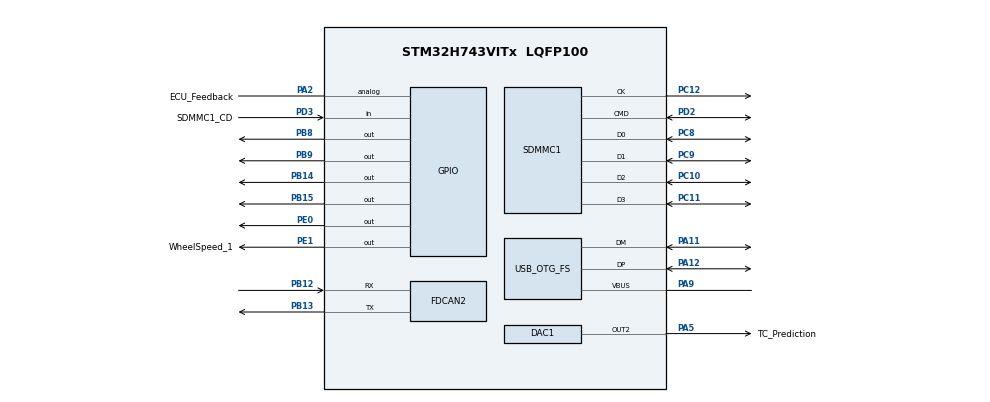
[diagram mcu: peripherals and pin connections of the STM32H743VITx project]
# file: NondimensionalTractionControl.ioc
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CORTEX_M7.AccessPermission_S-Cortex_Memory_Protection_Unit_Region1_Settings_S=MPU_REGION_PRIV_RO
CORTEX_M7.BaseAddress_S-Cortex_Memory_Protection_Unit_Region1_Settings_S=0x08000000
CORTEX_M7.CPU_DCache=Enabled
CORTEX_M7.CPU_ICache=Enabled
CORTEX_M7.Enable_S-Cortex_Memory_Protection_Unit_Region1_Settings_S=MPU_REGION_ENABLE
CORTEX_M7.IsCacheable_S-Cortex_Memory_Protection_Unit_Region1_Settings_S=MPU_ACCESS_CACHEABLE
CORTEX_M7.Size_S-Cortex_Memory_Protection_Unit_Region1_Settings_S=MPU_REGION_SIZE_2MB
CORTEX_M7.TypeExtField_S-Cortex_Memory_Protection_Unit_Region1_Settings_S=MPU_TEX_LEVEL1
CORTEX_M7.default_mode_Activation=1
DAC1.DAC_Channel-DAC_OUT2=DAC_CHANNEL_2
Dma.DMA_GENERATOR0.0.Direction=DMA_PERIPH_TO_MEMORY
Dma.DMA_GENERATOR0.0.EventEnable=DISABLE
Dma.DMA_GENERATOR0.0.FIFOMode=DMA_FIFOMODE_DISABLE
Dma.DMA_GENERATOR0.0.Instance=DMA1_Stream0
Dma.DMA_GENERATOR0.0.MemDataAlignment=DMA_MDATAALIGN_WORD
Dma.DMA_GENERATOR0.0.MemInc=DMA_MINC_ENABLE
Dma.DMA_GENERATOR0.0.Mode=DMA_CIRCULAR
Dma.DMA_GENERATOR0.0.PeriphDataAlignment=DMA_PDATAALIGN_WORD
Dma.DMA_GENERATOR0.0.PeriphInc=DMA_PINC_DISABLE
Dma.DMA_GENERATOR0.0.Polarity=HAL_DMAMUX_REQ_GEN_RISING
Dma.DMA_GENERATOR0.0.Priority=DMA_PRIORITY_HIGH
Dma.DMA_GENERATOR0.0.RequestNumber=1
Dma.DMA_GENERATOR0.0.SignalID=NONE
Dma.DMA_GENERATOR0.0.SyncEnable=DISABLE
Dma.DMA_GENERATOR0.0.SyncPolarity=HAL_DMAMUX_SYNC_NO_EVENT
Dma.DMA_GENERATOR0.0.SyncRequestNumber=1
Dma.DMA_GENERATOR0.0.SyncSignalID=NONE
Dma.Request0=DMA_GENERATOR0
FDCAN2.CalculateBaudRateNominal=166666
FDCAN2.CalculateTimeBitNominal=6000
FDCAN2.CalculateTimeQuantumNominal=2000.0
FREERTOS.Tasks01=defaultTask,24,128,StartDefaultTask,Default,NULL,Dynamic,NULL,NULL
FREERTOS.configUSE_NEWLIB_REENTRANT=1
IWDG1.Prescaler=IWDG_PRESCALER_32
IWDG1.Reload=999
IWDG1.Window=500
Mcu.Family=STM32H7
Mcu.Name=STM32H743VITx
Mcu.Package=LQFP100
NVIC.DMA1_Stream0_IRQn=true\:10\:0\:true\:false\:true\:true\:true\:true\:true
NVIC.DMAMUX1_OVR_IRQn=true\:5\:0\:false\:false\:true\:false\:false\:true\:true
NVIC.OTG_FS_IRQn=true\:5\:0\:false\:false\:true\:true\:false\:true\:true
NVIC.PriorityGroup=NVIC_PRIORITYGROUP_4
NVIC.TIM2_IRQn=true\:5\:0\:false\:false\:true\:true\:true\:true\:true
NVIC.TIM6_DAC_IRQn=true\:5\:0\:false\:false\:true\:false\:false\:true\:true
NVIC.TimeBase=TIM6_DAC_IRQn
NVIC.TimeBaseIP=TIM6
PA11.Mode=Device_Only
PA11.Signal=USB_OTG_FS_DM
PA12.Mode=Device_Only
PA12.Signal=USB_OTG_FS_DP
PA13\ (JTMS/SWDIO).Mode=Trace_Asynchronous_SW
PA13\ (JTMS/SWDIO).Signal=DEBUG_JTMS-SWDIO
PA14\ (JTCK/SWCLK).Mode=Trace_Asynchronous_SW
PA14\ (JTCK/SWCLK).Signal=DEBUG_JTCK-SWCLK
PA2.GPIO_Label=ECU_Feedback
PA2.Signal=GPIO_Analog
PA5.GPIO_Label=TC_Prediction
PA5.Signal=COMP_DAC12_group
PA9.Mode=Activate_VBUS
PA9.Signal=USB_OTG_FS_VBUS
PB12.Mode=FDCAN_Activate
PB12.Signal=FDCAN2_RX
PB13.Mode=FDCAN_Activate
PB13.Signal=FDCAN2_TX
PB14.Signal=GPIO_Output
PB15.Signal=GPIO_Output
PB3\ (JTDO/TRACESWO).Mode=Trace_Asynchronous_SW
PB3\ (JTDO/TRACESWO).Signal=DEBUG_JTDO-SWO
PB8.Signal=GPIO_Output
PB9.Signal=GPIO_Output
PC10.Mode=SD_4_bits_Wide_bus
PC10.Signal=SDMMC1_D2
PC11.Mode=SD_4_bits_Wide_bus
PC11.Signal=SDMMC1_D3
PC12.Mode=SD_4_bits_Wide_bus
PC12.Signal=SDMMC1_CK
PC8.Mode=SD_4_bits_Wide_bus
PC8.Signal=SDMMC1_D0
PC9.Mode=SD_4_bits_Wide_bus
PC9.Signal=SDMMC1_D1
PD2.Mode=SD_4_bits_Wide_bus
PD2.Signal=SDMMC1_CMD
PD3.GPIO_Label=SDMMC1_CD
PD3.Signal=GPIO_Input
PE0.Signal=GPIO_Output
PE1.GPIO_Label=WheelSpeed_1
PE1.Signal=GPIO_Output
PH0-OSC_IN\ (PH0).Mode=HSE-External-Clock-Source
PH0-OSC_IN\ (PH0).Signal=RCC_OSC_IN
ProjectManager.HeapSize=0x800
ProjectManager.StackSize=0x800
ProjectManager.TargetToolchain=STM32CubeIDE
RCC.ADCFreq_Value=72000000
RCC.APB1Freq_Value=120000000
RCC.APB2Freq_Value=120000000
RCC.APB3Freq_Value=120000000
RCC.APB4Freq_Value=120000000
RCC.CortexFreq_Value=480000000
RCC.D1PPRE=RCC_APB3_DIV2
RCC.D2PPRE1=RCC_APB1_DIV2
RCC.D2PPRE2=RCC_APB2_DIV2
RCC.D3PPRE=RCC_APB4_DIV2
RCC.DIVM1=1
RCC.DIVM2=1
RCC.DIVN1=120
RCC.DIVN2=18
RCC.DIVQ1=20
RCC.DIVR2=3
RCC.EnbaleCSS=true
RCC.FDCANCLockSelection=RCC_FDCANCLKSOURCE_HSE
RCC.HCLKFreq_Value=240000000
RCC.HPRE=RCC_HCLK_DIV2
RCC.HSE_VALUE=8000000
RCC.LockedElements=D1CPREOutput,SDMMCoutput
RCC.PLL2FRACN=0
RCC.PLL3FRACN=0
RCC.PLLFRACN=0
RCC.PLLSourceVirtual=RCC_PLLSOURCE_HSE
RCC.SYSCLKFreq_VALUE=480000000
RCC.SYSCLKSource=RCC_SYSCLKSOURCE_PLLCLK
RCC.USBFreq_Value=48000000
SH.COMP_DAC12_group.0=DAC1_OUT2,DAC_OUT2
STMicroelectronics.X-CUBE-AI.10.1.0.ActivationBufferSizeList=1956
STMicroelectronics.X-CUBE-AI.10.1.0.ActivationBuffers=pool0
STMicroelectronics.X-CUBE-AI.10.1.0.ActivationNames=pool0
STMicroelectronics.X-CUBE-AI.10.1.0.ActivationSizes=AI_NETWORK_DATA_ACTIVATION_1_SIZE
STMicroelectronics.X-CUBE-AI.10.1.0.HeapSize=0x800
STMicroelectronics.X-CUBE-AI.10.1.0.InternalRamActivationBufferMaxSize=AI_NETWORK_DATA_ACTIVATIONS_SIZE
STMicroelectronics.X-CUBE-AI.10.1.0.LatestDirectoryUsed-a3bddd4ec8f6f26f949c49dc56bf6e18b7fccf90c8280bdc512d254c8ab813ac=/Users/aayanmapara/Projects/NondimensionalTractionControl/ModelDevelopment/downloaded_models/new
STMicroelectronics.X-CUBE-AI.10.1.0.MaximumNumberOfInputLayer=1
STMicroelectronics.X-CUBE-AI.10.1.0.MaximumNumberOfOutputLayer=1
STMicroelectronics.X-CUBE-AI.10.1.0.MaximumSizeOfInputLayer=1
STMicroelectronics.X-CUBE-AI.10.1.0.MaximumSizeOfOutputLayer=1
STMicroelectronics.X-CUBE-AI.10.1.0.ModelActualCompression-a3bddd4ec8f6f26f949c49dc56bf6e18b7fccf90c8280bdc512d254c8ab813ac=0.0
STMicroelectronics.X-CUBE-AI.10.1.0.ModelCompression-a3bddd4ec8f6f26f949c49dc56bf6e18b7fccf90c8280bdc512d254c8ab813ac=None
STMicroelectronics.X-CUBE-AI.10.1.0.ModelFlashOccupation-a3bddd4ec8f6f26f949c49dc56bf6e18b7fccf90c8280bdc512d254c8ab813ac=12596
STMicroelectronics.X-CUBE-AI.10.1.0.ModelHashList=a3bddd4ec8f6f26f949c49dc56bf6e18b7fccf90c8280bdc512d254c8ab813ac
STMicroelectronics.X-CUBE-AI.10.1.0.ModelKind-a3bddd4ec8f6f26f949c49dc56bf6e18b7fccf90c8280bdc512d254c8ab813ac=TFLITE
STMicroelectronics.X-CUBE-AI.10.1.0.ModelMacc-a3bddd4ec8f6f26f949c49dc56bf6e18b7fccf90c8280bdc512d254c8ab813ac=889
STMicroelectronics.X-CUBE-AI.10.1.0.ModelName-a3bddd4ec8f6f26f949c49dc56bf6e18b7fccf90c8280bdc512d254c8ab813ac=network
STMicroelectronics.X-CUBE-AI.10.1.0.ModelNameList=network
STMicroelectronics.X-CUBE-AI.10.1.0.ModelRamOccupation-a3bddd4ec8f6f26f949c49dc56bf6e18b7fccf90c8280bdc512d254c8ab813ac=1956
STMicroelectronics.X-CUBE-AI.10.1.0.ModelStructureFile-a3bddd4ec8f6f26f949c49dc56bf6e18b7fccf90c8280bdc512d254c8ab813ac=ModelDevelopment/downloaded_models/new/model3.tflite
STMicroelectronics.X-CUBE-AI.10.1.0.ModelType-a3bddd4ec8f6f26f949c49dc56bf6e18b7fccf90c8280bdc512d254c8ab813ac=STM32Cube.AI MCU runtime
STMicroelectronics.X-CUBE-AI.10.1.0.ReadyForCodeGeneration=true
STMicroelectronics.X-CUBE-AI.10.1.0.StackSize=0x800
STMicroelectronics.X-CUBE-AI.10.1.0.WorkingBufferStartAddrList=0xFFFFFFFF
STMicroelectronics.X-CUBE-AI.10.1.0.XAaCUBEAaAICcArtificialOoIntelligenceJjCore=true
STMicroelectronics.X-CUBE-AI.10.1.0.copyWeightToRam=false
STMicroelectronics.X-CUBE-AI.10.1.0.customLayerConfigEnabled=false
STMicroelectronics.X-CUBE-AI.10.1.0.noOnnxIoTranspose=false
STMicroelectronics.X-CUBE-AI.10.1.0.outputDirectory=/Users/aayanmapara/.stm32cubemx/tire_slip_network_output
STMicroelectronics.X-CUBE-AI.10.1.0.useInputAllocation=true
STMicroelectronics.X-CUBE-AI.10.1.0.useOutputAllocation=true
USB_DEVICE.CLASS_NAME_FS=CDC
USB_DEVICE.VirtualMode-CDC_FS=Cdc
USB_DEVICE.VirtualModeFS=Cdc_FS
USB_OTG_FS.VirtualMode=Device_Only
VP_FATFS_VS_SDIO.Mode=SDIO
VP_FREERTOS_VS_CMSIS_V2.Mode=CMSIS_V2
VP_IWDG1_VS_IWDG.Mode=IWDG_Activate
VP_MEMORYMAP_VS_MEMORYMAP.Mode=CurAppReg
VP_STMicroelectronics.X-CUBE-AI_VS_ArtificialOoIntelligenceJjXAaCUBEAaAI_10.1.0.Mode=ArtificialOoIntelligenceJjXAaCUBEAaAI
VP_SYS_VS_tim6.Mode=TIM6
VP_TIM2_VS_ClockSourceINT.Mode=Internal
VP_USB_DEVICE_VS_USB_DEVICE_CDC_FS.Mode=CDC_FS
board=custom

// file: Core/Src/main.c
/* USER CODE BEGIN Header */
/**
  ******************************************************************************
  * @file           : main.c
  * @brief          : Main program body
  ******************************************************************************
  * @attention
  *
  * Copyright (c) 2025 STMicroelectronics.
  * All rights reserved.
  *
  * This software is licensed under terms that can be found in the LICENSE file
  * in the root directory of this software component.
  * If no LICENSE file comes with this software, it is provided AS-IS.
  *
  ******************************************************************************
  */
/* USER CODE END Header */
#include "main.h"
#include "cmsis_os.h"
#include "fatfs.h"
#include "usb_device.h"

DAC_HandleTypeDef hdac1;

FDCAN_HandleTypeDef hfdcan2;

IWDG_HandleTypeDef hiwdg1;

SD_HandleTypeDef hsd1;

TIM_HandleTypeDef htim2;

DMA_HandleTypeDef hdma_dma_generator0;
/* Definitions for defaultTask */
osThreadId_t defaultTaskHandle;
const osThreadAttr_t defaultTask_attributes = {
  .name = "defaultTask",
  .stack_size = 128 * 4,
  .priority = (osPriority_t) osPriorityNormal,
};
/* USER CODE BEGIN PV */
static ai_handle tire_slip_network = AI_HANDLE_NULL;
static ai_u8 activations[AI_TIRE_SLIP_NETWORK_DATA_ACTIVATIONS_SIZE];

static ai_float in_data[AI_TIRE_SLIP_NETWORK_IN_1_SIZE];
static ai_float out_data[AI_TIRE_SLIP_NETWORK_OUT_1_SIZE];

static ai_buffer ai_input[AI_TIRE_SLIP_NETWORK_IN_NUM] = AI_TIRE_SLIP_NETWORK_IN_1_SET_VIC(in_data);
static ai_buffer ai_output[AI_TIRE_SLIP_NETWORK_OUT_NUM] = AI_TIRE_SLIP_NETWORK_OUT_1_SET_VIC(out_data);

float SCALER_MEAN[5] = {19.630303697626477, -0.0005450365189715463, 59.8901043966616, 120.48587937144882, 59.00885398270266};
float SCALER_SCALE[5] = {8.66180044582203, 0.14460143717972843, 23.107923307685642, 57.82262435123635, 84.05533340078773};
/* USER CODE END PV */

void SystemClock_Config(void);
static void MPU_Config(void);
static void MX_GPIO_Init(void);
static void MX_DMA_Init(void);
static void MX_IWDG1_Init(void);
static void MX_TIM2_Init(void);
static void MX_SDMMC1_SD_Init(void);
static void MX_DAC1_Init(void);
static void MX_FDCAN2_Init(void);
void StartDefaultTask(void *argument);

int main(void)
{

  /* MPU Configuration--------------------------------------------------------*/
  MPU_Config();

  /* Enable the CPU Cache */

  /* Enable I-Cache---------------------------------------------------------*/
  SCB_EnableICache();

  /* Enable D-Cache---------------------------------------------------------*/
  SCB_EnableDCache();

  /* MCU Configuration--------------------------------------------------------*/

  /* Reset of all peripherals, Initializes the Flash interface and the Systick. */
  HAL_Init();

  /* Configure the system clock */
  SystemClock_Config();

  /* Initialize all configured peripherals */
  MX_GPIO_Init();
  MX_DMA_Init();
  MX_IWDG1_Init();
  MX_TIM2_Init();
  MX_SDMMC1_SD_Init();
  MX_FATFS_Init();
  MX_DAC1_Init();
  MX_FDCAN2_Init();

  /* Init scheduler */
  osKernelInitialize();

  /* Create the thread(s) */
  /* creation of defaultTask */
  defaultTaskHandle = osThreadNew(StartDefaultTask, NULL, &defaultTask_attributes);

  /* Start scheduler */
  osKernelStart();

  /* We should never get here as control is now taken by the scheduler */

  /* Infinite loop */
  while (1)
  {

  }
}

void SystemClock_Config(void)
{
  RCC_OscInitTypeDef RCC_OscInitStruct = {0};
  RCC_ClkInitTypeDef RCC_ClkInitStruct = {0};

  /** Supply configuration update enable
  */
  HAL_PWREx_ConfigSupply(PWR_LDO_SUPPLY);

  /** Configure the main internal regulator output voltage
  */
  __HAL_PWR_VOLTAGESCALING_CONFIG(PWR_REGULATOR_VOLTAGE_SCALE0);

  while(!__HAL_PWR_GET_FLAG(PWR_FLAG_VOSRDY)) {}

  /** Initializes the RCC Oscillators according to the specified parameters
  * in the RCC_OscInitTypeDef structure.
  */
  RCC_OscInitStruct.OscillatorType = RCC_OSCILLATORTYPE_LSI|RCC_OSCILLATORTYPE_HSE;
  RCC_OscInitStruct.HSEState = RCC_HSE_BYPASS;
  RCC_OscInitStruct.LSIState = RCC_LSI_ON;
  RCC_OscInitStruct.PLL.PLLState = RCC_PLL_ON;
  RCC_OscInitStruct.PLL.PLLSource = RCC_PLLSOURCE_HSE;
  RCC_OscInitStruct.PLL.PLLM = 1;
  RCC_OscInitStruct.PLL.PLLN = 120;
  RCC_OscInitStruct.PLL.PLLP = 2;
  RCC_OscInitStruct.PLL.PLLQ = 20;
  RCC_OscInitStruct.PLL.PLLR = 2;
  RCC_OscInitStruct.PLL.PLLRGE = RCC_PLL1VCIRANGE_3;
  RCC_OscInitStruct.PLL.PLLVCOSEL = RCC_PLL1VCOWIDE;
  RCC_OscInitStruct.PLL.PLLFRACN = 0;
  if (HAL_RCC_OscConfig(&RCC_OscInitStruct) != HAL_OK)
  {
    Error_Handler();
  }

  /** Initializes the CPU, AHB and APB buses clocks
  */
  RCC_ClkInitStruct.ClockType = RCC_CLOCKTYPE_HCLK|RCC_CLOCKTYPE_SYSCLK
                              |RCC_CLOCKTYPE_PCLK1|RCC_CLOCKTYPE_PCLK2
                              |RCC_CLOCKTYPE_D3PCLK1|RCC_CLOCKTYPE_D1PCLK1;
  RCC_ClkInitStruct.SYSCLKSource = RCC_SYSCLKSOURCE_PLLCLK;
  RCC_ClkInitStruct.SYSCLKDivider = RCC_SYSCLK_DIV1;
  RCC_ClkInitStruct.AHBCLKDivider = RCC_HCLK_DIV2;
  RCC_ClkInitStruct.APB3CLKDivider = RCC_APB3_DIV2;
  RCC_ClkInitStruct.APB1CLKDivider = RCC_APB1_DIV2;
  RCC_ClkInitStruct.APB2CLKDivider = RCC_APB2_DIV2;
  RCC_ClkInitStruct.APB4CLKDivider = RCC_APB4_DIV2;

  if (HAL_RCC_ClockConfig(&RCC_ClkInitStruct, FLASH_LATENCY_4) != HAL_OK)
  {
    Error_Handler();
  }

  /** Enables the Clock Security System
  */
  HAL_RCC_EnableCSS();
}

static void MX_DAC1_Init(void)
{

  DAC_ChannelConfTypeDef sConfig = {0};

  /** DAC Initialization
  */
  hdac1.Instance = DAC1;
  if (HAL_DAC_Init(&hdac1) != HAL_OK)
  {
    Error_Handler();
  }

  /** DAC channel OUT2 config
  */
  sConfig.DAC_SampleAndHold = DAC_SAMPLEANDHOLD_DISABLE;
  sConfig.DAC_Trigger = DAC_TRIGGER_NONE;
  sConfig.DAC_OutputBuffer = DAC_OUTPUTBUFFER_ENABLE;
  sConfig.DAC_ConnectOnChipPeripheral = DAC_CHIPCONNECT_DISABLE;
  sConfig.DAC_UserTrimming = DAC_TRIMMING_FACTORY;
  if (HAL_DAC_ConfigChannel(&hdac1, &sConfig, DAC_CHANNEL_2) != HAL_OK)
  {
    Error_Handler();
  }

}

static void MX_FDCAN2_Init(void)
{

  hfdcan2.Instance = FDCAN2;
  hfdcan2.Init.FrameFormat = FDCAN_FRAME_CLASSIC;
  hfdcan2.Init.Mode = FDCAN_MODE_NORMAL;
  hfdcan2.Init.AutoRetransmission = DISABLE;
  hfdcan2.Init.TransmitPause = DISABLE;
  hfdcan2.Init.ProtocolException = DISABLE;
  hfdcan2.Init.NominalPrescaler = 16;
  hfdcan2.Init.NominalSyncJumpWidth = 1;
  hfdcan2.Init.NominalTimeSeg1 = 1;
  hfdcan2.Init.NominalTimeSeg2 = 1;
  hfdcan2.Init.DataPrescaler = 1;
  hfdcan2.Init.DataSyncJumpWidth = 1;
  hfdcan2.Init.DataTimeSeg1 = 1;
  hfdcan2.Init.DataTimeSeg2 = 1;
  hfdcan2.Init.MessageRAMOffset = 0;
  hfdcan2.Init.StdFiltersNbr = 0;
  hfdcan2.Init.ExtFiltersNbr = 0;
  hfdcan2.Init.RxFifo0ElmtsNbr = 0;
  hfdcan2.Init.RxFifo0ElmtSize = FDCAN_DATA_BYTES_8;
  hfdcan2.Init.RxFifo1ElmtsNbr = 0;
  hfdcan2.Init.RxFifo1ElmtSize = FDCAN_DATA_BYTES_8;
  hfdcan2.Init.RxBuffersNbr = 0;
  hfdcan2.Init.RxBufferSize = FDCAN_DATA_BYTES_8;
  hfdcan2.Init.TxEventsNbr = 0;
  hfdcan2.Init.TxBuffersNbr = 0;
  hfdcan2.Init.TxFifoQueueElmtsNbr = 0;
  hfdcan2.Init.TxFifoQueueMode = FDCAN_TX_FIFO_OPERATION;
  hfdcan2.Init.TxElmtSize = FDCAN_DATA_BYTES_8;
  if (HAL_FDCAN_Init(&hfdcan2) != HAL_OK)
  {
    Error_Handler();
  }

}

static void MX_IWDG1_Init(void)
{

  hiwdg1.Instance = IWDG1;
  hiwdg1.Init.Prescaler = IWDG_PRESCALER_32;
  hiwdg1.Init.Window = 500;
  hiwdg1.Init.Reload = 999;
  if (HAL_IWDG_Init(&hiwdg1) != HAL_OK)
  {
    Error_Handler();
  }

}

static void MX_SDMMC1_SD_Init(void)
{

  hsd1.Instance = SDMMC1;
  hsd1.Init.ClockEdge = SDMMC_CLOCK_EDGE_RISING;
  hsd1.Init.ClockPowerSave = SDMMC_CLOCK_POWER_SAVE_DISABLE;
  hsd1.Init.BusWide = SDMMC_BUS_WIDE_4B;
  hsd1.Init.HardwareFlowControl = SDMMC_HARDWARE_FLOW_CONTROL_DISABLE;
  hsd1.Init.ClockDiv = 0;

}

static void MX_TIM2_Init(void)
{

  TIM_ClockConfigTypeDef sClockSourceConfig = {0};
  TIM_MasterConfigTypeDef sMasterConfig = {0};

  htim2.Instance = TIM2;
  htim2.Init.Prescaler = 0;
  htim2.Init.CounterMode = TIM_COUNTERMODE_UP;
  htim2.Init.Period = 4294967295;
  htim2.Init.ClockDivision = TIM_CLOCKDIVISION_DIV1;
  htim2.Init.AutoReloadPreload = TIM_AUTORELOAD_PRELOAD_DISABLE;
  if (HAL_TIM_Base_Init(&htim2) != HAL_OK)
  {
    Error_Handler();
  }
  sClockSourceConfig.ClockSource = TIM_CLOCKSOURCE_INTERNAL;
  if (HAL_TIM_ConfigClockSource(&htim2, &sClockSourceConfig) != HAL_OK)
  {
    Error_Handler();
  }
  sMasterConfig.MasterOutputTrigger = TIM_TRGO_RESET;
  sMasterConfig.MasterSlaveMode = TIM_MASTERSLAVEMODE_DISABLE;
  if (HAL_TIMEx_MasterConfigSynchronization(&htim2, &sMasterConfig) != HAL_OK)
  {
    Error_Handler();
  }

}

static void MX_DMA_Init(void)
{

  /* DMA controller clock enable */
  __HAL_RCC_DMA1_CLK_ENABLE();

  /* Configure DMA request hdma_dma_generator0 on DMA1_Stream0 */
  hdma_dma_generator0.Instance = DMA1_Stream0;
  hdma_dma_generator0.Init.Request = DMA_REQUEST_GENERATOR0;
  hdma_dma_generator0.Init.Direction = DMA_PERIPH_TO_MEMORY;
  hdma_dma_generator0.Init.PeriphInc = DMA_PINC_DISABLE;
  hdma_dma_generator0.Init.MemInc = DMA_MINC_ENABLE;
  hdma_dma_generator0.Init.PeriphDataAlignment = DMA_PDATAALIGN_WORD;
  hdma_dma_generator0.Init.MemDataAlignment = DMA_MDATAALIGN_WORD;
  hdma_dma_generator0.Init.Mode = DMA_CIRCULAR;
  hdma_dma_generator0.Init.Priority = DMA_PRIORITY_HIGH;
  hdma_dma_generator0.Init.FIFOMode = DMA_FIFOMODE_DISABLE;
  if (HAL_DMA_Init(&hdma_dma_generator0) != HAL_OK)
  {
    Error_Handler( );
  }

  /* DMA interrupt init */
  /* DMA1_Stream0_IRQn interrupt configuration */
  HAL_NVIC_SetPriority(DMA1_Stream0_IRQn, 10, 0);
  HAL_NVIC_EnableIRQ(DMA1_Stream0_IRQn);
  /* DMAMUX1_OVR_IRQn interrupt configuration */
  HAL_NVIC_SetPriority(DMAMUX1_OVR_IRQn, 5, 0);
  HAL_NVIC_EnableIRQ(DMAMUX1_OVR_IRQn);

}

static void MX_GPIO_Init(void)
{
  GPIO_InitTypeDef GPIO_InitStruct = {0};

  /* GPIO Ports Clock Enable */
  __HAL_RCC_GPIOE_CLK_ENABLE();
  __HAL_RCC_GPIOC_CLK_ENABLE();
  __HAL_RCC_GPIOH_CLK_ENABLE();
  __HAL_RCC_GPIOA_CLK_ENABLE();
  __HAL_RCC_GPIOB_CLK_ENABLE();
  __HAL_RCC_GPIOD_CLK_ENABLE();

  /*Configure GPIO pin Output Level */
  HAL_GPIO_WritePin(GPIOB, GPIO_PIN_14|GPIO_PIN_15|GPIO_PIN_8|GPIO_PIN_9, GPIO_PIN_RESET);

  /*Configure GPIO pin Output Level */
  HAL_GPIO_WritePin(GPIOE, GPIO_PIN_0|WheelSpeed_1_Pin, GPIO_PIN_RESET);

  /*Configure GPIO pins : PE2 PE3 PE4 PE5
                           PE6 PE7 PE8 PE9
                           PE10 PE11 PE12 PE13
                           PE14 PE15 */
  GPIO_InitStruct.Pin = GPIO_PIN_2|GPIO_PIN_3|GPIO_PIN_4|GPIO_PIN_5
                          |GPIO_PIN_6|GPIO_PIN_7|GPIO_PIN_8|GPIO_PIN_9
                          |GPIO_PIN_10|GPIO_PIN_11|GPIO_PIN_12|GPIO_PIN_13
                          |GPIO_PIN_14|GPIO_PIN_15;
  GPIO_InitStruct.Mode = GPIO_MODE_ANALOG;
  GPIO_InitStruct.Pull = GPIO_NOPULL;
  HAL_GPIO_Init(GPIOE, &GPIO_InitStruct);

  /*Configure GPIO pins : PC13 PC14 PC15 PC0
                           PC1 PC2 PC3 PC4
                           PC5 PC6 PC7 */
  GPIO_InitStruct.Pin = GPIO_PIN_13|GPIO_PIN_14|GPIO_PIN_15|GPIO_PIN_0
                          |GPIO_PIN_1|GPIO_PIN_2|GPIO_PIN_3|GPIO_PIN_4
                          |GPIO_PIN_5|GPIO_PIN_6|GPIO_PIN_7;
  GPIO_InitStruct.Mode = GPIO_MODE_ANALOG;
  GPIO_InitStruct.Pull = GPIO_NOPULL;
  HAL_GPIO_Init(GPIOC, &GPIO_InitStruct);

  /*Configure GPIO pin : PH1 */
  GPIO_InitStruct.Pin = GPIO_PIN_1;
  GPIO_InitStruct.Mode = GPIO_MODE_ANALOG;
  GPIO_InitStruct.Pull = GPIO_NOPULL;
  HAL_GPIO_Init(GPIOH, &GPIO_InitStruct);

  /*Configure GPIO pins : PA0 PA1 ECU_Feedback_Pin PA3
                           PA4 PA6 PA7 PA8
                           PA10 PA15 */
  GPIO_InitStruct.Pin = GPIO_PIN_0|GPIO_PIN_1|ECU_Feedback_Pin|GPIO_PIN_3
                          |GPIO_PIN_4|GPIO_PIN_6|GPIO_PIN_7|GPIO_PIN_8
                          |GPIO_PIN_10|GPIO_PIN_15;
  GPIO_InitStruct.Mode = GPIO_MODE_ANALOG;
  GPIO_InitStruct.Pull = GPIO_NOPULL;
  HAL_GPIO_Init(GPIOA, &GPIO_InitStruct);

  /*Configure GPIO pins : PB0 PB1 PB2 PB10
                           PB11 PB4 PB5 PB6
                           PB7 */
  GPIO_InitStruct.Pin = GPIO_PIN_0|GPIO_PIN_1|GPIO_PIN_2|GPIO_PIN_10
                          |GPIO_PIN_11|GPIO_PIN_4|GPIO_PIN_5|GPIO_PIN_6
                          |GPIO_PIN_7;
  GPIO_InitStruct.Mode = GPIO_MODE_ANALOG;
  GPIO_InitStruct.Pull = GPIO_NOPULL;
  HAL_GPIO_Init(GPIOB, &GPIO_InitStruct);

  /*Configure GPIO pins : PB14 PB15 PB8 PB9 */
  GPIO_InitStruct.Pin = GPIO_PIN_14|GPIO_PIN_15|GPIO_PIN_8|GPIO_PIN_9;
  GPIO_InitStruct.Mode = GPIO_MODE_OUTPUT_PP;
  GPIO_InitStruct.Pull = GPIO_NOPULL;
  GPIO_InitStruct.Speed = GPIO_SPEED_FREQ_LOW;
  HAL_GPIO_Init(GPIOB, &GPIO_InitStruct);

  /*Configure GPIO pins : PD8 PD9 PD10 PD11
                           PD12 PD13 PD14 PD15
                           PD0 PD1 PD4 PD5
                           PD6 PD7 */
  GPIO_InitStruct.Pin = GPIO_PIN_8|GPIO_PIN_9|GPIO_PIN_10|GPIO_PIN_11
                          |GPIO_PIN_12|GPIO_PIN_13|GPIO_PIN_14|GPIO_PIN_15
                          |GPIO_PIN_0|GPIO_PIN_1|GPIO_PIN_4|GPIO_PIN_5
                          |GPIO_PIN_6|GPIO_PIN_7;
  GPIO_InitStruct.Mode = GPIO_MODE_ANALOG;
  GPIO_InitStruct.Pull = GPIO_NOPULL;
  HAL_GPIO_Init(GPIOD, &GPIO_InitStruct);

  /*Configure GPIO pin : SDMMC1_CD_Pin */
  GPIO_InitStruct.Pin = SDMMC1_CD_Pin;
  GPIO_InitStruct.Mode = GPIO_MODE_INPUT;
  GPIO_InitStruct.Pull = GPIO_NOPULL;
  HAL_GPIO_Init(SDMMC1_CD_GPIO_Port, &GPIO_InitStruct);

  /*Configure GPIO pins : PE0 WheelSpeed_1_Pin */
  GPIO_InitStruct.Pin = GPIO_PIN_0|WheelSpeed_1_Pin;
  GPIO_InitStruct.Mode = GPIO_MODE_OUTPUT_PP;
  GPIO_InitStruct.Pull = GPIO_NOPULL;
  GPIO_InitStruct.Speed = GPIO_SPEED_FREQ_LOW;
  HAL_GPIO_Init(GPIOE, &GPIO_InitStruct);

}

void StartDefaultTask(void *argument)
{
  /* init code for USB_DEVICE */
  MX_USB_DEVICE_Init();
  for(;;)
  {
    osDelay(1);
  }
}

 /* MPU Configuration */

void MPU_Config(void)
{
  MPU_Region_InitTypeDef MPU_InitStruct = {0};

  /* Disables the MPU */
  HAL_MPU_Disable();

  /** Initializes and configures the Region and the memory to be protected
  */
  MPU_InitStruct.Enable = MPU_REGION_ENABLE;
  MPU_InitStruct.Number = MPU_REGION_NUMBER0;
  MPU_InitStruct.BaseAddress = 0x0;
  MPU_InitStruct.Size = MPU_REGION_SIZE_4GB;
  MPU_InitStruct.SubRegionDisable = 0x87;
  MPU_InitStruct.TypeExtField = MPU_TEX_LEVEL0;
  MPU_InitStruct.AccessPermission = MPU_REGION_NO_ACCESS;
  MPU_InitStruct.DisableExec = MPU_INSTRUCTION_ACCESS_DISABLE;
  MPU_InitStruct.IsShareable = MPU_ACCESS_SHAREABLE;
  MPU_InitStruct.IsCacheable = MPU_ACCESS_NOT_CACHEABLE;
  MPU_InitStruct.IsBufferable = MPU_ACCESS_NOT_BUFFERABLE;

  HAL_MPU_ConfigRegion(&MPU_InitStruct);

  /** Initializes and configures the Region and the memory to be protected
  */
  MPU_InitStruct.Number = MPU_REGION_NUMBER1;
  MPU_InitStruct.BaseAddress = 0x08000000;
  MPU_InitStruct.Size = MPU_REGION_SIZE_2MB;
  MPU_InitStruct.SubRegionDisable = 0x0;
  MPU_InitStruct.TypeExtField = MPU_TEX_LEVEL1;
  MPU_InitStruct.AccessPermission = MPU_REGION_PRIV_RO;
  MPU_InitStruct.DisableExec = MPU_INSTRUCTION_ACCESS_ENABLE;
  MPU_InitStruct.IsShareable = MPU_ACCESS_NOT_SHAREABLE;
  MPU_InitStruct.IsCacheable = MPU_ACCESS_CACHEABLE;

  HAL_MPU_ConfigRegion(&MPU_InitStruct);
  /* Enables the MPU */
  HAL_MPU_Enable(MPU_PRIVILEGED_DEFAULT);

}

void HAL_TIM_PeriodElapsedCallback(TIM_HandleTypeDef *htim)
{
  if (htim->Instance == TIM6)
  {
    HAL_IncTick();
  }
}

void Error_Handler(void)
{
  __disable_irq();
  while (1)
  {
  }
}
